# N575F145_v1 register map
File version: 1.0
Registers are 32-bit, read-write, reset 0x0 unless marked. A register's access mark holds for its fields unless they carry their own. Offsets are from the block's base; [hi:lo] are bit positions; {n}, {i} and the like mark numbered series.

## GCR — GCR Register Map
Base 0x50000000
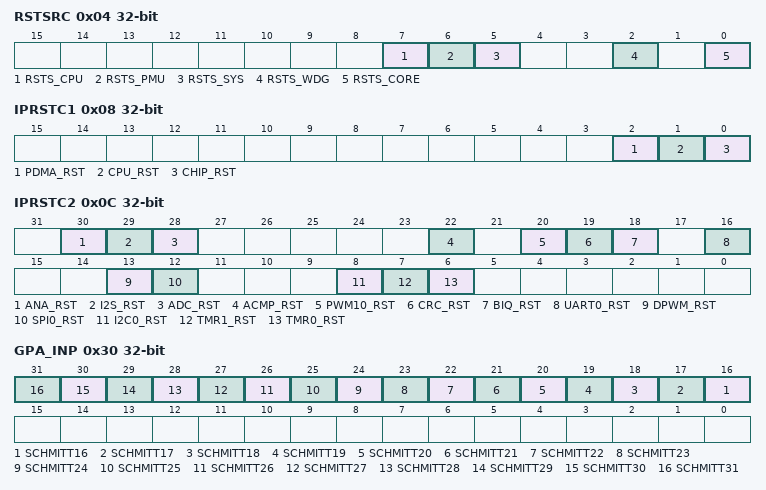
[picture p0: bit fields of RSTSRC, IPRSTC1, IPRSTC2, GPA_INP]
0x04 RSTSRC (reset mask 0xFFFFFF00) — System Reset Source Register
  [7] RSTS_CPU — Reset Source From CPU. The RSTS_CPU flag is set by hardware if software writes CPU_RST (IPRSTCR1[1]) with a "1" to reset Cortex-M0 CPU kernel and Flash memory controller (FMC). This bit is cleared by writing 1 to itself.
    0=No reset from CPU; 1=The Cortex-M0 CPU kernel and FMC has been reset by software setting CPU_RST to 1
  [6] RSTS_PMU — Reset Source From PMU. The RSTS_PMU flag is set if the PMU. This bit is cleared by writing 1 to itself.
    0=No reset from PMU; 1=PMU reset the system from a power down/standby event
  [5] RSTS_SYS — Reset Source From MCU. The RSTS_SYS flag is set if the previous reset source originates from the Cortex_M0 kernel. This bit is cleared by writing 1 to itself.
    0=No reset from MCU; 1=The Cortex_M0 MCU issued a reset signal to reset the system by software writing 1 to bit SYSRESTREQ(AIRCR[2], Application Interrupt and Reset Control Register) in system control registers of Cortex_M0 kernel
  [2] RSTS_WDG — Reset Source From WDG. The RSTS_WDG flag is set if pervious reset source originates from the Watch-Dog module. This bit is cleared by writing 1 to itself.
    0=No reset from Watch-Dog; 1=The Watch-Dog module issued the reset signal to reset the system
  [0] RSTS_CORE — Reset Source From CORE. The RSTS_CORE flag is set if the core has been reset. Possible sources of reset are a Power-On Reset (POR), RESETn Pin Reset or PMU reset. This bit is cleared by writing 1 to itself.
    0=No reset from CORE; 1=Core was reset by hardware block
0x08 IPRSTC1 — IP Reset Control Resister1
  [2] PDMA_RST — PDMA Controller Reset. Set "1" will generate a reset signal to the PDMA Block. User needs to set this bit to "0" to release from the reset state
    0=Normal operation; 1=PDMA IP reset
  [1] CPU_RST — CPU Kernel One Shot Reset. Setting this bit will reset the CPU kernel and Flash Memory Controller(FMC), this bit will automatically return to "0" after the 2 clock cycles. This bit is a protected bit, to program first issue the unlock sequence (see Protected Register Lock Key Register (REGLOCK))
    0=Normal; 1=Reset CPU
  [0] CHIP_RST — CHIP One Shot Reset. Set this bit will reset the whole chip, this bit will automatically return to "0" after the 2 clock cycles. CHIP_RST has same behavior as POR reset, all the chip modules are reset and the chip configuration settings from flash are reloaded. This bit is a protected bit, to program first issue the unlock sequence (see Protected Register Lock Key Register (REGLOCK))
    0=Normal; 1=Reset CHIP
0x0C IPRSTC2 — IP Reset Control Resister2
  [all] fields
    0=Normal Operation; 1=Reset
  [30] ANA_RST — Analog Block Control Reset
  [29] I2S_RST — I2S Controller Reset
  [28] ADC_RST — ADC Controller Reset
  [22] ACMP_RST — Analog Comparator Reset
  [20] PWM10_RST — PWM10 controller Reset
  [19] CRC_RST — CRC Generation Block Reset
  [18] BIQ_RST — Biquad Filter Block Reset
  [16] UART0_RST — UART0 Controller Reset
  [13] DPWM_RST — DPWM Speaker Driver Reset
  [12] SPI0_RST — SPI0 Controller Reset
  [8] I2C0_RST — I2C0 Controller Reset
  [7] TMR1_RST — Timer1 Controller Reset
  [6] TMR0_RST — Timer0 Controller Reset
0x30 GPA_INP — GPIOA input type control register
  [all] fields
    0=GPIOA[15:0] I/O input Schmitt Trigger disabled; 1=GPIOA[15:0] I/O input Schmitt Trigger enabled
  [n] SCHMITT{n} (n=16..31) — Schmitt Trigger. This register controls whether the GPIO input buffer Schmitt trigger is enabled.
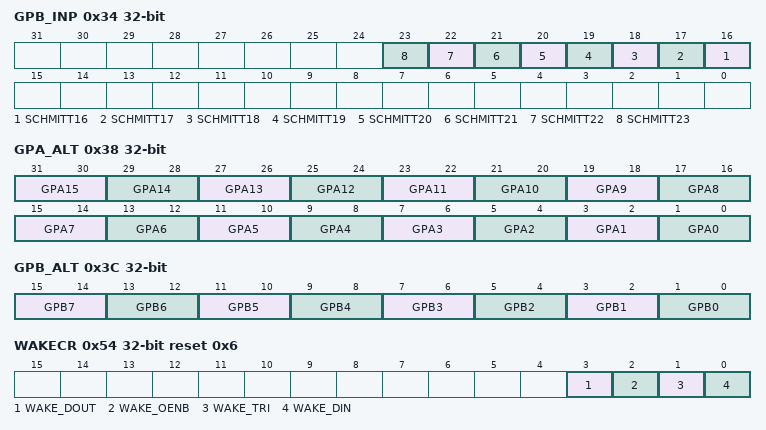
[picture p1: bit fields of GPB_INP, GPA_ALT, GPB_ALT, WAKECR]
0x34 GPB_INP — GPIOB input type control register
  [all] fields
    0=GPIOB(port 0 ~ port 7) I/O input Schmitt Trigger disabled; 1=GPIOB(port 0 ~ port 7) I/O input Schmitt Trigger enabled
  [n] SCHMITT{n} (n=16..23) — Schmitt Trigger. This register controls whether the GPIO input buffer Schmitt trigger is enabled.
0x38 GPA_ALT — GPIOA multiple function control register
  [31:30] GPA15 — Alternate Function Setting For GPA15
    0=GPIO; 1=TM1; 2=SDIN
  [29:28] GPA14 — Alternate Function Setting For GPA14
    0=GPIO; 1=TM0; 2=SDCLK; 3=SDCLKn
  [27:26] GPA13 — Alternate Function Setting For GPA13
    0=GPIO; 1=PWM1; 2=SPKM; 3=I2S_BCLK
  [25:24] GPA12 — Alternate Function Setting For GPA12
    0=GPIO; 1=PWM0; 2=SPKP; 3=I2S_FS
  [23:22] GPA11 — Alternate Function Setting For GPA11
    0=GPIO; 1=I2C_SCL; 2=I2S_SDO; 3=UART_CTSn
  [21:20] GPA10 — Alternate Function Setting For GPA10
    0=GPIO; 1=I2C_SDA; 2=I2S_SDI; 3=UART_RTSn
  [19:18] GPA9 — Alternate Function Setting For GPA9
    0=GPIO; 1=UART_RX; 2=I2S_BCLK
  [17:16] GPA8 — Alternate Function Setting For GPA8
    0=GPIO; 1=UART_TX; 2=I2S_FS
  [15:14] GPA7 — Alternate Function Setting For GPA7
    0=GPIO; 1=I2S_SDO
  [13:12] GPA6 — Alternate Function Setting For GPA6
    0=GPIO; 1=I2S_SDI
  [11:10] GPA5 — Alternate Function Setting For GPA5
    0=GPIO; 1=I2S_BCLK
  [9:8] GPA4 — Alternate Function Setting For GPA4
    0=GPIO; 1=I2S_FS
  [7:6] GPA3 — Alternate Function Setting For GPA3
    0=GPIO; 1=SPI_MISO0; 2=I2C_SDA
  [5:4] GPA2 — Alternate Function Setting For GPA3
    0=GPIO; 1=SPI_SSB0
  [3:2] GPA1 — Alternate Function Setting For GPA2
    0=GPIO; 1=SPI_SCLK; 2=I2C_SCL
  [1:0] GPA0 — Alternate Function Setting For GPA1
    0=GPIO; 1=SPI_MOSI0; 2=MCLK
0x3C GPB_ALT — GPIOB multiple function control register
  [15:14] GPB7 — Alternate Function Setting For GPB7
    0=GPIO; 1=I2S_SDO; 2=CMP7
  [13:12] GPB6 — Alternate Function Setting For GPB6
    0=GPIO; 1=I2S_SDI; 2=CMP6; 3=SPI_MOSI1
  [11:10] GPB5 — Alternate Function Setting For GPB5
    0=GPIO; 1=PWM1B; 2=CMP5; 3=SPI_MISO1
  [9:8] GPB4 — Alternate Function Setting For GPB4
    0=GPIO; 1=PWM0B; 2=CMP4; 3=SPI_MOSI0
  [7:6] GPB3 — Alternate Function Setting For GPB3
    0=GPIO; 1=I2C_SDA; 2=CMP3; 3=SPI_MISO0
  [5:4] GPB2 — Alternate Function Setting For GPB2
    0=GPIO; 1=I2C_SCL; 2=CMP2; 3=SPI_SCLK
  [3:2] GPB1 — Alternate Function Setting For GPB1
    0=GPIO; 1=MCLK; 2=CMP1; 3=SPI_SSB1
  [1:0] GPB0 — Alternate Function Setting For GPB0
    0=GPIO; 1=SPI_SSB1; 2=CMP0; 3=SPI_SSB0
0x54 WAKECR reset 0x6 — WAKEUP pin control register
  [3] WAKE_DOUT — Wakeup Output State
    0=drive Low if the corresponding output mode bit is set (default); 1=drive High if the corresponding output mode bit is set
  [2] WAKE_OENB — Wakeup Pin Output Enable Bar
    0=drive WAKE_DOUT to pin; 1=tristate (default)
  [1] WAKE_TRI — Wakeup Pin Pull-up Control. This signal is latched in deep power down and preserved.
    0=pull-up enable; 1=tristate (default)
  [0] WAKE_DIN — State Of Wakeup Pin. Read only.
0x100 REGLOCK — Register Lock Key Address register
  [0] RegUnLock — Protected Register Unlock Register
    0=Protected registers are locked. Any write to the target register is ignored; 1=Protected registers are unlocked
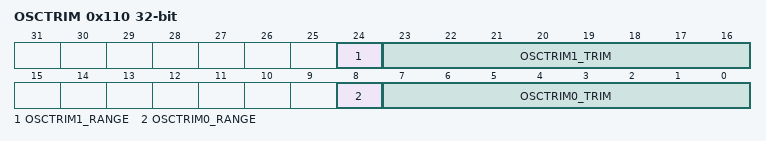
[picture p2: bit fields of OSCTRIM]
0x110 OSCTRIM reset not defined — Oscillator Frequency Adjustment control register
  [24] OSCTRIM1_RANGE — Range Bit For Oscillator
    0=high range; 1=low range
  [23:16] OSCTRIM1_TRIM — 8 Bit Trim For Oscillator. TRIM[7:5] are 8 coarse trim ranges which overlap in frequency. TRIM[4:0] are 32 fine trim steps of approximately 0.5% resolution.
  [8] OSCTRIM0_RANGE — Range Bit For Oscillator
    0=high range; 1=low range
  [7:0] OSCTRIM0_TRIM — 8 Bit Trim For Oscillator. TRIM[7:5] are 8 coarse trim ranges which overlap in frequency. TRIM[4:0] are 32 fine trim steps of approximately 0.5% resolution.
0x114 OSC16K reset not defined — 16K Oscillator trim register
